# STM32H7A3x register map
File version: 2.0
CPU: CM7 r0p1, little endian, MPU, FPU, 4 interrupt priority bits
Registers are 32-bit, read-write, reset 0x0 unless marked. A register's access mark holds for its fields unless they carry their own. Offsets are from the block's base; [hi:lo] are bit positions; {n}, {i} and the like mark numbered series.

## MDIOS — Management data input/output slave
Base 0x40009400
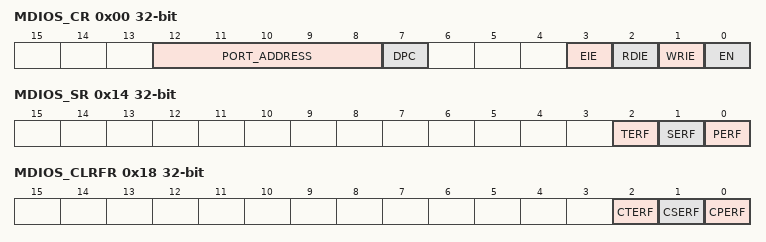
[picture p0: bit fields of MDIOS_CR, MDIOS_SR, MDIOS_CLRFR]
0x00 MDIOS_CR — MDIOS configuration register
  [12:8] PORT_ADDRESS — Slaves's address
  [7] DPC — Disable Preamble Check
  [3] EIE — Error interrupt enable
  [2] RDIE — Register Read Interrupt Enable
  [1] WRIE — Register write interrupt enable
  [0] EN — Peripheral enable
0x04 MDIOS_WRFR ro — MDIOS write flag register
  [31:0] WRF — Write flags for MDIO registers 0 to 31
0x08 MDIOS_CWRFR — MDIOS clear write flag register
  [31:0] CWRF — Clear the write flag
0x0C MDIOS_RDFR ro — MDIOS read flag register
  [31:0] RDF — Read flags for MDIO registers 0 to 31
0x10 MDIOS_CRDFR — MDIOS clear read flag register
  [31:0] CRDF — Clear the read flag
0x14 MDIOS_SR ro — MDIOS status register
  [2] TERF — Turnaround error flag
  [1] SERF — Start error flag
  [0] PERF — Preamble error flag
0x18 MDIOS_CLRFR — MDIOS clear flag register
  [2] CTERF — Clear the turnaround error flag
  [1] CSERF — Clear the start error flag
  [0] CPERF — Clear the preamble error flag
{0x1C+4i} MDIOS_DINR{i} ro (i=0..31) — MDIOS input data register {i}
  [15:0] DIN{i} — Input data received from MDIO Master during write frames
{0x9C+4i} MDIOS_DOUTR{i} (i=0..31) — MDIOS output data register {i}
  [15:0] DOUT{i} — Output data sent to MDIO Master during read frames

## MPU — Memory protection unit
Base 0xE000ED90
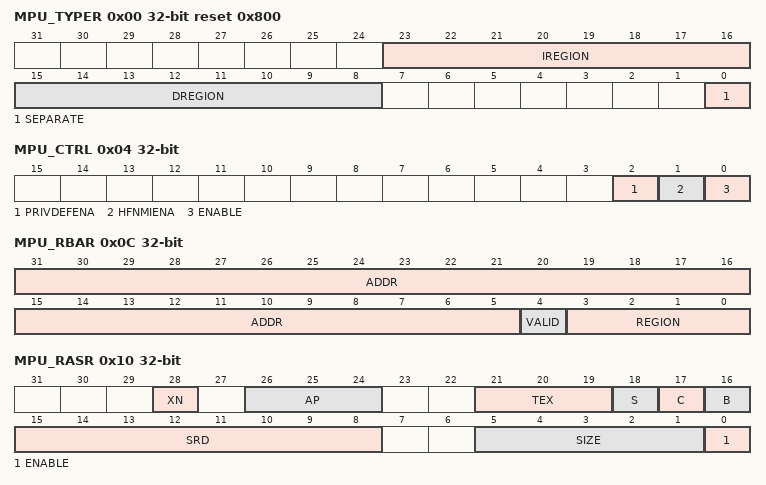
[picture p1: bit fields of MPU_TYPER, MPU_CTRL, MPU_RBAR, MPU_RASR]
0x00 MPU_TYPER ro reset 0x800 — MPU type register
  [23:16] IREGION — Number of MPU instruction regions
  [15:8] DREGION — Number of MPU data regions
  [0] SEPARATE — Separate flag
0x04 MPU_CTRL — MPU control register
  [2] PRIVDEFENA — Enable priviliged software access to default memory map
  [1] HFNMIENA — Enables the operation of MPU during hard fault
  [0] ENABLE — Enables the MPU
0x08 MPU_RNR — MPU region number register
  [7:0] REGION — MPU region
0x0C MPU_RBAR — MPU region base address register
  [31:5] ADDR — Region base address field
  [4] VALID — MPU region number valid
  [3:0] REGION — MPU region field
0x10 MPU_RASR — MPU region attribute and size register
  [28] XN — Instruction access disable bit
  [26:24] AP — Access permission
  [21:19] TEX — memory attribute
  [18] S — Shareable memory attribute
  [17] C — memory attribute
  [16] B — memory attribute
  [15:8] SRD — Subregion disable bits
  [5:1] SIZE — Size of the MPU protection region
  [0] ENABLE — Region enable bit.

## NVIC — Nested Vectored Interrupt Controller
Base 0xE000E100
{0x0+4i} ISER{i} (i=0..2) — Interrupt Set-Enable Register
  [31:0] SETENA
{0x80+4i} ICER{i} (i=0..2) — Interrupt Clear-Enable Register
  [31:0] CLRENA
{0x100+4i} ISPR{i} (i=0..2) — Interrupt Set-Pending Register
  [31:0] SETPEND
{0x180+4i} ICPR{i} (i=0..2) — Interrupt Clear-Pending Register
  [31:0] CLRPEND
{0x200+4i} IABR{i} ro (i=0..2) — Interrupt Active Bit Register
  [31:0] ACTIVE
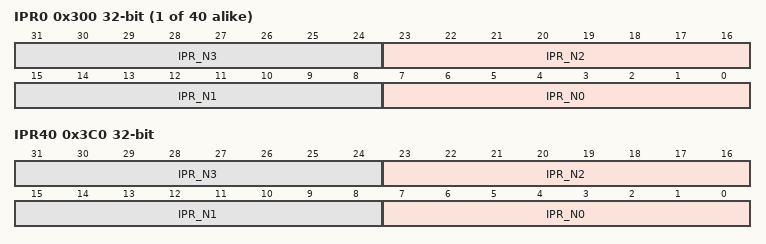
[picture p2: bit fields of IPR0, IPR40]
{0x300+4i} IPR{i} (i=0..39) — Interrupt Priority Register
  [8n+7:8n] IPR_N{n} (n=0..3)
0x3A0 ISER3 — Interrupt Set-Enable Register
  [31:0] SETENA
0x3A4 ISER4 — Interrupt Set-Enable Register
  [31:0] SETENA
0x3A8 ICER3 — Interrupt Clear-Enable Register
  [31:0] CLRENA
0x3AC ICER4 — Interrupt Clear-Enable Register
  [31:0] CLRENA
0x3B0 ISPR3 — Interrupt Set-Pending Register
  [31:0] SETPEND
0x3B4 ISPR4 — Interrupt Set-Pending Register
  [31:0] SETPEND
0x3B8 IABR3 ro — Interrupt Active Bit Register
  [31:0] ACTIVE
0x3BC IABR4 ro — Interrupt Active Bit Register
  [31:0] ACTIVE
0x3C0 IPR40 — Interrupt Priority Register
  [8n+7:8n] IPR_N{n} (n=0..3)

## NVIC_STIR — Nested vectored interrupt controller
Base 0xE000EF00
0x00 STIR — Software trigger interrupt register
  [8:0] INTID — Software generated interrupt ID
